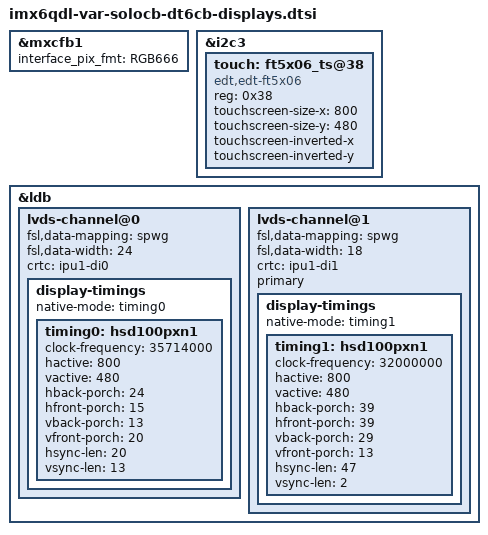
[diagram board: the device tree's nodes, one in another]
/*
 * Copyright (C) 2016 Variscite, Ltd. All Rights Reserved
 *
 * Copyright 2012 Freescale Semiconductor, Inc.
 * Copyright 2011 Linaro Ltd.
 *
 * The code contained herein is licensed under the GNU General Public
 * License. You may obtain a copy of the GNU General Public License
 * Version 2 or later at the following locations:
 *
 * http://www.opensource.org/licenses/gpl-license.html
 * http://www.gnu.org/copyleft/gpl.html
 *
 * Capacitive Display for VAR-SoloCustomBoard and VAR-DT6CustomBoard
 */

&mxcfb1 {
	interface_pix_fmt = "RGB666";
};

&i2c3 {
	touch: ft5x06_ts@38 {
		compatible = "edt,edt-ft5x06";
		reg = <0x38>;
		touchscreen-size-x = <800>;
		touchscreen-size-y = <480>;
		touchscreen-inverted-x;
		touchscreen-inverted-y;
	};
};

&ldb {
	status = "okay";

	lvds-channel@0 {
		fsl,data-mapping = "spwg";
		fsl,data-width = <24>;
		crtc = "ipu1-di0";
		status = "okay";

		display-timings {
			native-mode = <&timing0>;
			timing0: hsd100pxn1 {
				clock-frequency = <35714000>;
				hactive = <800>;
				vactive = <480>;
				hback-porch = <24>;
				hfront-porch = <15>;
				vback-porch = <13>;
				vfront-porch = <20>;
				hsync-len = <20>;
				vsync-len = <13>;
			};
		};
	};

	lvds-channel@1 {
		fsl,data-mapping = "spwg";
		fsl,data-width = <18>;
		crtc = "ipu1-di1";
		primary;
		status = "okay";

		display-timings {
			native-mode = <&timing1>;
			timing1: hsd100pxn1 {
				clock-frequency = <32000000>;
				hactive = <800>;
				vactive = <480>;
				hback-porch = <39>;
				hfront-porch = <39>;
				vback-porch = <29>;
				vfront-porch = <13>;
				hsync-len = <47>;
				vsync-len = <2>;
			};
		};
	};
};
